AUTOSAR XML (schema 00047)
# (C) 2021 HYUNDAI AUTOEVER Corp.
package /Svc_NvM/ClientServerInterfaces
  5 x client server interface, all with is-service=true, service-kind=NON-VOLATILE-RAM-MANAGER:
    NvMAdmin
      operation SetBlockProtection: possible-error=[NvMAdmin/E_NOT_OK, NvMAdmin/E_OK]
        arg ProtectionEnabled: type=boolean, direction=IN
      error E_NOT_OK: error-code=1
      error E_OK: error-code=0
    NvMMirror
      operation ReadRamBlockFromNvM: possible-error=[NvMMirror/E_NOT_OK, NvMMirror/E_OK]
        arg SrcPtr: type=ConstVoidPtr, direction=IN
      operation WriteRamBlockToNvM: possible-error=[NvMMirror/E_NOT_OK, NvMMirror/E_OK]
        arg DstPtr: type=VoidPtr, direction=IN
      error E_NOT_OK: error-code=1
      error E_OK: error-code=0
    NvMNotifyInitBlock
      operation InitBlock: possible-error=NvMNotifyInitBlock/E_OK
        arg InitBlockRequest: type=NvM_InitBlockRequestType, direction=IN
      error E_OK: error-code=0
    NvMNotifyJobFinished
      operation JobFinished: possible-error=NvMNotifyJobFinished/E_OK
        arg BlockRequest: type=NvM_BlockRequestType, direction=IN
        arg JobResult: type=NvM_RequestResultType, direction=IN
      error E_OK: error-code=0
    NvMService
      12 x operation, all with possible-error=[NvMService/E_NOT_OK, NvMService/E_OK]:
        EraseBlock
        GetDataIndex
          arg DataIndexPtr: type=uint8, direction=OUT
        GetErrorStatus
          arg RequestResultPtr: type=NvM_RequestResultType, direction=OUT
        InvalidateNvBlock
        ReadBlock
          arg DstPtr: type=VoidPtr, direction=IN
        ReadPRAMBlock
        RestoreBlockDefaults
          arg DstPtr: type=VoidPtr, direction=IN
        RestorePRAMBlockDefaults
        SetDataIndex
          arg DataIndex: type=uint8, direction=IN
        SetRamBlockStatus
          arg BlockChanged: type=boolean, direction=IN
        WriteBlock
          arg SrcPtr: type=ConstVoidPtr, direction=IN
        WritePRAMBlock
      error E_NOT_OK: error-code=1
      error E_OK: error-code=0
package /Svc_NvM/ImplementationDataTypes
  6 x impl type:
    ConstVoidPtr: category=DATA_REFERENCE, sw-pointer-target-props={target-category=VALUE, base-type=void, sw-impl-policy=CONST}
    NvM_BlockIdType: implementation-data-type=uint16
    NvM_BlockRequestType: compu {0=NVM_READ_BLOCK, 1=NVM_WRITE_BLOCK, 2=NVM_RESTORE_BLOCK_DEFAULTS, 3=NVM_ERASE_NV_BLOCK, 4=NVM_INVALIDATE_NV_BLOCK, 5=NVM_READ_ALL_BLOCK}, implementation-data-type=uint8
    NvM_InitBlockRequestType: compu {0=NVM_INIT_READ_BLOCK, 1=NVM_INIT_RESTORE_BLOCK_DEFAULTS, 2=NVM_INIT_READ_ALL_BLOCK, 3=NVM_INIT_FIRST_INIT_ALL}, implementation-data-type=uint8
    NvM_RequestResultType: compu {0=NVM_REQ_OK, 1=NVM_REQ_NOT_OK, 2=NVM_REQ_PENDING, 3=NVM_REQ_INTEGRITY_FAILED, 4=NVM_REQ_BLOCK_SKIPPED, 5=NVM_REQ_NV_INVALIDATED, 6=NVM_REQ_CANCELED, 7=NVM_REQ_REDUNDANCY_FAILED, 8=NVM_REQ_RESTORED_FROM_ROM, 9=NVM_MAXVALUE}, implementation-data-type=uint8
    VoidPtr: category=DATA_REFERENCE, sw-pointer-target-props={target-category=VALUE, base-type=void}
package /Svc_NvM/ServiceSwComponentTypes
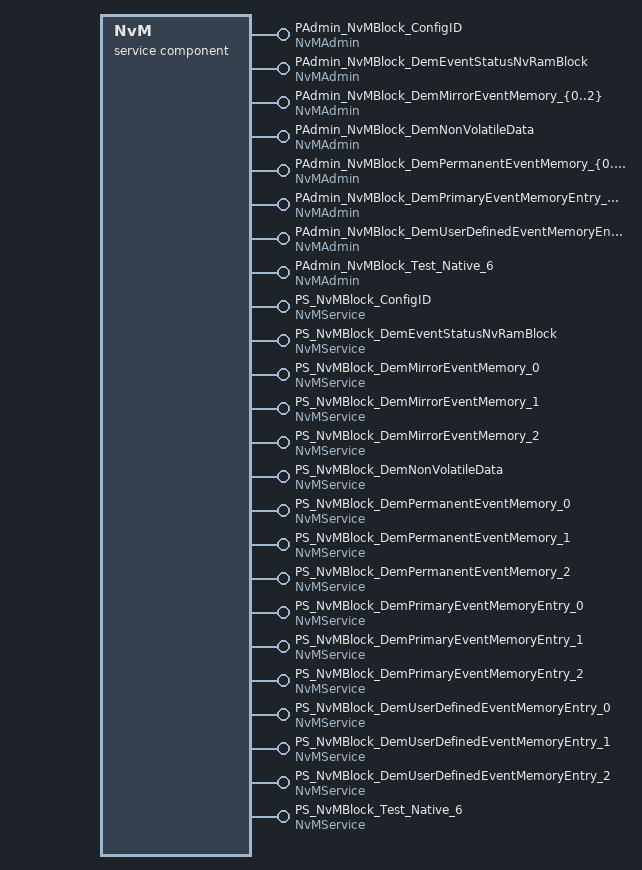
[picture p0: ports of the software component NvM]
  service sw component type NvM
    32 x provide port:
      PAdmin_NvMBlock_ConfigID: server-com-spec{operation=SetBlockProtection, queue-length=1}, provided-interface=NvMAdmin  # This port provides the Supervision status interface of NvMBlock_ConfigID to a SWC.
      PAdmin_NvMBlock_DemEventStatusNvRamBlock: server-com-spec{operation=SetBlockProtection, queue-length=1}, provided-interface=NvMAdmin  # This port provides the Supervision status interface of NvMBlock_DemEventStatusNvRamBlock to a SWC.
      PAdmin_NvMBlock_DemMirrorEventMemory_{0..2}: server-com-spec{operation=SetBlockProtection, queue-length=1}, provided-interface=NvMAdmin  # This port provides the Supervision status interface of NvMBlock_DemMirrorEventMemory_{0..2} to a SWC.
      PAdmin_NvMBlock_DemNonVolatileData: server-com-spec{operation=SetBlockProtection, queue-length=1}, provided-interface=NvMAdmin  # This port provides the Supervision status interface of NvMBlock_DemNonVolatileData to a SWC.
      PAdmin_NvMBlock_DemPermanentEventMemory_{0..2}: server-com-spec{operation=SetBlockProtection, queue-length=1}, provided-interface=NvMAdmin  # This port provides the Supervision status interface of NvMBlock_DemPermanentEventMemory_{0..2} to a SWC.
      PAdmin_NvMBlock_DemPrimaryEventMemoryEntry_{0..2}: server-com-spec{operation=SetBlockProtection, queue-length=1}, provided-interface=NvMAdmin  # This port provides the Supervision status interface of NvMBlock_DemPrimaryEventMemoryEntry_{0..2} to a SWC.
      PAdmin_NvMBlock_DemUserDefinedEventMemoryEntry_{0..2}: server-com-spec{operation=SetBlockProtection, queue-length=1}, provided-interface=NvMAdmin  # This port provides the Supervision status interface of NvMBlock_DemUserDefinedEventMemoryEntry_{0..2} to a SWC.
      PAdmin_NvMBlock_Test_Native_6: server-com-spec{operation=SetBlockProtection, queue-length=1}, provided-interface=NvMAdmin  # This port provides the Supervision status interface of NvMBlock_Test_Native_6 to a SWC.
      PS_NvMBlock_ConfigID: provided-interface=NvMService  # This port provides the Supervision status interface of NvMBlock_ConfigID to a SWC.
        provided-com-specs:
          operation=EraseBlock, queue-length=1
          operation=GetDataIndex, queue-length=1
          operation=GetErrorStatus, queue-length=1
          operation=InvalidateNvBlock, queue-length=1
          operation=ReadBlock, queue-length=1
          operation=ReadPRAMBlock, queue-length=1
          operation=RestoreBlockDefaults, queue-length=1
          operation=RestorePRAMBlockDefaults, queue-length=1
          operation=SetDataIndex, queue-length=1
          operation=SetRamBlockStatus, queue-length=1
          operation=WriteBlock, queue-length=1
          operation=WritePRAMBlock, queue-length=1
      PS_NvMBlock_DemEventStatusNvRamBlock: provided-interface=NvMService  # This port provides the Supervision status interface of NvMBlock_DemEventStatusNvRamBlock to a SWC.
        provided-com-specs:
          operation=EraseBlock, queue-length=1
          operation=GetDataIndex, queue-length=1
          operation=GetErrorStatus, queue-length=1
          operation=InvalidateNvBlock, queue-length=1
          operation=ReadBlock, queue-length=1
          operation=ReadPRAMBlock, queue-length=1
          operation=RestoreBlockDefaults, queue-length=1
          operation=RestorePRAMBlockDefaults, queue-length=1
          operation=SetDataIndex, queue-length=1
          operation=SetRamBlockStatus, queue-length=1
          operation=WriteBlock, queue-length=1
          operation=WritePRAMBlock, queue-length=1
      PS_NvMBlock_DemMirrorEventMemory_0: provided-interface=NvMService  # This port provides the Supervision status interface of NvMBlock_DemMirrorEventMemory_0 to a SWC.
        provided-com-specs:
          operation=EraseBlock, queue-length=1
          operation=GetDataIndex, queue-length=1
          operation=GetErrorStatus, queue-length=1
          operation=InvalidateNvBlock, queue-length=1
          operation=ReadBlock, queue-length=1
          operation=ReadPRAMBlock, queue-length=1
          operation=RestoreBlockDefaults, queue-length=1
          operation=RestorePRAMBlockDefaults, queue-length=1
          operation=SetDataIndex, queue-length=1
          operation=SetRamBlockStatus, queue-length=1
          operation=WriteBlock, queue-length=1
          operation=WritePRAMBlock, queue-length=1
      PS_NvMBlock_DemMirrorEventMemory_1: provided-interface=NvMService  # This port provides the Supervision status interface of NvMBlock_DemMirrorEventMemory_1 to a SWC.
        provided-com-specs:
          operation=EraseBlock, queue-length=1
          operation=GetDataIndex, queue-length=1
          operation=GetErrorStatus, queue-length=1
          operation=InvalidateNvBlock, queue-length=1
          operation=ReadBlock, queue-length=1
          operation=ReadPRAMBlock, queue-length=1
          operation=RestoreBlockDefaults, queue-length=1
          operation=RestorePRAMBlockDefaults, queue-length=1
          operation=SetDataIndex, queue-length=1
          operation=SetRamBlockStatus, queue-length=1
          operation=WriteBlock, queue-length=1
          operation=WritePRAMBlock, queue-length=1
      PS_NvMBlock_DemMirrorEventMemory_2: provided-interface=NvMService  # This port provides the Supervision status interface of NvMBlock_DemMirrorEventMemory_2 to a SWC.
        provided-com-specs:
          operation=EraseBlock, queue-length=1
          operation=GetDataIndex, queue-length=1
          operation=GetErrorStatus, queue-length=1
          operation=InvalidateNvBlock, queue-length=1
          operation=ReadBlock, queue-length=1
          operation=ReadPRAMBlock, queue-length=1
          operation=RestoreBlockDefaults, queue-length=1
          operation=RestorePRAMBlockDefaults, queue-length=1
          operation=SetDataIndex, queue-length=1
          operation=SetRamBlockStatus, queue-length=1
          operation=WriteBlock, queue-length=1
          operation=WritePRAMBlock, queue-length=1
      PS_NvMBlock_DemNonVolatileData: provided-interface=NvMService  # This port provides the Supervision status interface of NvMBlock_DemNonVolatileData to a SWC.
        provided-com-specs:
          operation=EraseBlock, queue-length=1
          operation=GetDataIndex, queue-length=1
          operation=GetErrorStatus, queue-length=1
          operation=InvalidateNvBlock, queue-length=1
          operation=ReadBlock, queue-length=1
          operation=ReadPRAMBlock, queue-length=1
          operation=RestoreBlockDefaults, queue-length=1
          operation=RestorePRAMBlockDefaults, queue-length=1
          operation=SetDataIndex, queue-length=1
          operation=SetRamBlockStatus, queue-length=1
          operation=WriteBlock, queue-length=1
          operation=WritePRAMBlock, queue-length=1
      PS_NvMBlock_DemPermanentEventMemory_0: provided-interface=NvMService  # This port provides the Supervision status interface of NvMBlock_DemPermanentEventMemory_0 to a SWC.
        provided-com-specs:
          operation=EraseBlock, queue-length=1
          operation=GetDataIndex, queue-length=1
          operation=GetErrorStatus, queue-length=1
          operation=InvalidateNvBlock, queue-length=1
          operation=ReadBlock, queue-length=1
          operation=ReadPRAMBlock, queue-length=1
          operation=RestoreBlockDefaults, queue-length=1
          operation=RestorePRAMBlockDefaults, queue-length=1
          operation=SetDataIndex, queue-length=1
          operation=SetRamBlockStatus, queue-length=1
          operation=WriteBlock, queue-length=1
          operation=WritePRAMBlock, queue-length=1
      PS_NvMBlock_DemPermanentEventMemory_1: provided-interface=NvMService  # This port provides the Supervision status interface of NvMBlock_DemPermanentEventMemory_1 to a SWC.
        provided-com-specs:
          operation=EraseBlock, queue-length=1
          operation=GetDataIndex, queue-length=1
          operation=GetErrorStatus, queue-length=1
          operation=InvalidateNvBlock, queue-length=1
          operation=ReadBlock, queue-length=1
          operation=ReadPRAMBlock, queue-length=1
          operation=RestoreBlockDefaults, queue-length=1
          operation=RestorePRAMBlockDefaults, queue-length=1
          operation=SetDataIndex, queue-length=1
          operation=SetRamBlockStatus, queue-length=1
          operation=WriteBlock, queue-length=1
          operation=WritePRAMBlock, queue-length=1
      PS_NvMBlock_DemPermanentEventMemory_2: provided-interface=NvMService  # This port provides the Supervision status interface of NvMBlock_DemPermanentEventMemory_2 to a SWC.
        provided-com-specs:
          operation=EraseBlock, queue-length=1
          operation=GetDataIndex, queue-length=1
          operation=GetErrorStatus, queue-length=1
          operation=InvalidateNvBlock, queue-length=1
          operation=ReadBlock, queue-length=1
          operation=ReadPRAMBlock, queue-length=1
          operation=RestoreBlockDefaults, queue-length=1
          operation=RestorePRAMBlockDefaults, queue-length=1
          operation=SetDataIndex, queue-length=1
          operation=SetRamBlockStatus, queue-length=1
          operation=WriteBlock, queue-length=1
          operation=WritePRAMBlock, queue-length=1
      PS_NvMBlock_DemPrimaryEventMemoryEntry_0: provided-interface=NvMService  # This port provides the Supervision status interface of NvMBlock_DemPrimaryEventMemoryEntry_0 to a SWC.
        provided-com-specs:
          operation=EraseBlock, queue-length=1
          operation=GetDataIndex, queue-length=1
          operation=GetErrorStatus, queue-length=1
          operation=InvalidateNvBlock, queue-length=1
          operation=ReadBlock, queue-length=1
          operation=ReadPRAMBlock, queue-length=1
          operation=RestoreBlockDefaults, queue-length=1
          operation=RestorePRAMBlockDefaults, queue-length=1
          operation=SetDataIndex, queue-length=1
          operation=SetRamBlockStatus, queue-length=1
          operation=WriteBlock, queue-length=1
          operation=WritePRAMBlock, queue-length=1
      PS_NvMBlock_DemPrimaryEventMemoryEntry_1: provided-interface=NvMService  # This port provides the Supervision status interface of NvMBlock_DemPrimaryEventMemoryEntry_1 to a SWC.
        provided-com-specs:
          operation=EraseBlock, queue-length=1
          operation=GetDataIndex, queue-length=1
          operation=GetErrorStatus, queue-length=1
          operation=InvalidateNvBlock, queue-length=1
          operation=ReadBlock, queue-length=1
          operation=ReadPRAMBlock, queue-length=1
          operation=RestoreBlockDefaults, queue-length=1
          operation=RestorePRAMBlockDefaults, queue-length=1
          operation=SetDataIndex, queue-length=1
          operation=SetRamBlockStatus, queue-length=1
          operation=WriteBlock, queue-length=1
          operation=WritePRAMBlock, queue-length=1
      PS_NvMBlock_DemPrimaryEventMemoryEntry_2: provided-interface=NvMService  # This port provides the Supervision status interface of NvMBlock_DemPrimaryEventMemoryEntry_2 to a SWC.
        provided-com-specs:
          operation=EraseBlock, queue-length=1
          operation=GetDataIndex, queue-length=1
          operation=GetErrorStatus, queue-length=1
          operation=InvalidateNvBlock, queue-length=1
          operation=ReadBlock, queue-length=1
          operation=ReadPRAMBlock, queue-length=1
          operation=RestoreBlockDefaults, queue-length=1
          operation=RestorePRAMBlockDefaults, queue-length=1
          operation=SetDataIndex, queue-length=1
          operation=SetRamBlockStatus, queue-length=1
          operation=WriteBlock, queue-length=1
          operation=WritePRAMBlock, queue-length=1
      PS_NvMBlock_DemUserDefinedEventMemoryEntry_0: provided-interface=NvMService  # This port provides the Supervision status interface of NvMBlock_DemUserDefinedEventMemoryEntry_0 to a SWC.
        provided-com-specs:
          operation=EraseBlock, queue-length=1
          operation=GetDataIndex, queue-length=1
          operation=GetErrorStatus, queue-length=1
          operation=InvalidateNvBlock, queue-length=1
          operation=ReadBlock, queue-length=1
          operation=ReadPRAMBlock, queue-length=1
          operation=RestoreBlockDefaults, queue-length=1
          operation=RestorePRAMBlockDefaults, queue-length=1
          operation=SetDataIndex, queue-length=1
          operation=SetRamBlockStatus, queue-length=1
          operation=WriteBlock, queue-length=1
          operation=WritePRAMBlock, queue-length=1
      PS_NvMBlock_DemUserDefinedEventMemoryEntry_1: provided-interface=NvMService  # This port provides the Supervision status interface of NvMBlock_DemUserDefinedEventMemoryEntry_1 to a SWC.
        provided-com-specs:
          operation=EraseBlock, queue-length=1
          operation=GetDataIndex, queue-length=1
          operation=GetErrorStatus, queue-length=1
          operation=InvalidateNvBlock, queue-length=1
          operation=ReadBlock, queue-length=1
          operation=ReadPRAMBlock, queue-length=1
          operation=RestoreBlockDefaults, queue-length=1
          operation=RestorePRAMBlockDefaults, queue-length=1
          operation=SetDataIndex, queue-length=1
          operation=SetRamBlockStatus, queue-length=1
          operation=WriteBlock, queue-length=1
          operation=WritePRAMBlock, queue-length=1
      PS_NvMBlock_DemUserDefinedEventMemoryEntry_2: provided-interface=NvMService  # This port provides the Supervision status interface of NvMBlock_DemUserDefinedEventMemoryEntry_2 to a SWC.
        provided-com-specs:
          operation=EraseBlock, queue-length=1
          operation=GetDataIndex, queue-length=1
          operation=GetErrorStatus, queue-length=1
          operation=InvalidateNvBlock, queue-length=1
          operation=ReadBlock, queue-length=1
          operation=ReadPRAMBlock, queue-length=1
          operation=RestoreBlockDefaults, queue-length=1
          operation=RestorePRAMBlockDefaults, queue-length=1
          operation=SetDataIndex, queue-length=1
          operation=SetRamBlockStatus, queue-length=1
          operation=WriteBlock, queue-length=1
          operation=WritePRAMBlock, queue-length=1
      PS_NvMBlock_Test_Native_6: provided-interface=NvMService  # This port provides the Supervision status interface of NvMBlock_Test_Native_6 to a SWC.
        provided-com-specs:
          operation=EraseBlock, queue-length=1
          operation=GetDataIndex, queue-length=1
          operation=GetErrorStatus, queue-length=1
          operation=InvalidateNvBlock, queue-length=1
          operation=ReadBlock, queue-length=1
          operation=ReadPRAMBlock, queue-length=1
          operation=RestoreBlockDefaults, queue-length=1
          operation=RestorePRAMBlockDefaults, queue-length=1
          operation=SetDataIndex, queue-length=1
          operation=SetRamBlockStatus, queue-length=1
          operation=WriteBlock, queue-length=1
          operation=WritePRAMBlock, queue-length=1
    behavior IB_NvM: handle-termination-and-restart=NO-SUPPORT
      208 x operation invoked event:
        OperationInvokedEvent_PAdmin_NvMBlock_ConfigID_SetBlockProtection: start-on-event=SetBlockProtection, operation=PAdmin_NvMBlock_ConfigID.SetBlockProtection
        OperationInvokedEvent_PAdmin_NvMBlock_DemEventStatusNvRamBlock_SetBlockProtection: start-on-event=SetBlockProtection, operation=PAdmin_NvMBlock_DemEventStatusNvRamBlock.SetBlockProtection
        OperationInvokedEvent_PAdmin_NvMBlock_DemMirrorEventMemory_{0..2}_SetBlockProtection: start-on-event=SetBlockProtection, operation=PAdmin_NvMBlock_DemMirrorEventMemory_{0..2}.SetBlockProtection
        OperationInvokedEvent_PAdmin_NvMBlock_DemNonVolatileData_SetBlockProtection: start-on-event=SetBlockProtection, operation=PAdmin_NvMBlock_DemNonVolatileData.SetBlockProtection
        OperationInvokedEvent_PAdmin_NvMBlock_DemPermanentEventMemory_{0..2}_SetBlockProtection: start-on-event=SetBlockProtection, operation=PAdmin_NvMBlock_DemPermanentEventMemory_{0..2}.SetBlockProtection
        OperationInvokedEvent_PAdmin_NvMBlock_DemPrimaryEventMemoryEntry_{0..2}_SetBlockProtection: start-on-event=SetBlockProtection, operation=PAdmin_NvMBlock_DemPrimaryEventMemoryEntry_{0..2}.SetBlockProtection
        OperationInvokedEvent_PAdmin_NvMBlock_DemUserDefinedEventMemoryEntry_{0..2}_SetBlockProtection: start-on-event=SetBlockProtection, operation=PAdmin_NvMBlock_DemUserDefinedEventMemoryEntry_{0..2}.SetBlockProtection
        OperationInvokedEvent_PAdmin_NvMBlock_Test_Native_6_SetBlockProtection: start-on-event=SetBlockProtection, operation=PAdmin_NvMBlock_Test_Native_6.SetBlockProtection
        OperationInvokedEvent_PS_NvMBlock_ConfigID_EraseBlock: start-on-event=EraseBlock, operation=PS_NvMBlock_ConfigID.EraseBlock
        OperationInvokedEvent_PS_NvMBlock_ConfigID_GetDataIndex: start-on-event=GetDataIndex, operation=PS_NvMBlock_ConfigID.GetDataIndex
        OperationInvokedEvent_PS_NvMBlock_ConfigID_GetErrorStatus: start-on-event=GetErrorStatus, operation=PS_NvMBlock_ConfigID.GetErrorStatus
        OperationInvokedEvent_PS_NvMBlock_ConfigID_InvalidateNvBlock: start-on-event=InvalidateNvBlock, operation=PS_NvMBlock_ConfigID.InvalidateNvBlock
        OperationInvokedEvent_PS_NvMBlock_ConfigID_ReadBlock: start-on-event=ReadBlock, operation=PS_NvMBlock_ConfigID.ReadBlock
        OperationInvokedEvent_PS_NvMBlock_ConfigID_ReadPRAMBlock: start-on-event=ReadPRAMBlock, operation=PS_NvMBlock_ConfigID.ReadPRAMBlock
        OperationInvokedEvent_PS_NvMBlock_ConfigID_RestoreBlockDefaults: start-on-event=RestoreBlockDefaults, operation=PS_NvMBlock_ConfigID.RestoreBlockDefaults
        OperationInvokedEvent_PS_NvMBlock_ConfigID_RestorePRAMBlockDefaults: start-on-event=RestorePRAMBlockDefaults, operation=PS_NvMBlock_ConfigID.RestorePRAMBlockDefaults
        OperationInvokedEvent_PS_NvMBlock_ConfigID_SetDataIndex: start-on-event=SetDataIndex, operation=PS_NvMBlock_ConfigID.SetDataIndex
        OperationInvokedEvent_PS_NvMBlock_ConfigID_SetRamBlockStatus: start-on-event=SetRamBlockStatus, operation=PS_NvMBlock_ConfigID.SetRamBlockStatus
        OperationInvokedEvent_PS_NvMBlock_ConfigID_WriteBlock: start-on-event=WriteBlock, operation=PS_NvMBlock_ConfigID.WriteBlock
        OperationInvokedEvent_PS_NvMBlock_ConfigID_WritePRAMBlock: start-on-event=WritePRAMBlock, operation=PS_NvMBlock_ConfigID.WritePRAMBlock
        OperationInvokedEvent_PS_NvMBlock_DemEventStatusNvRamBlock_EraseBlock: start-on-event=EraseBlock, operation=PS_NvMBlock_DemEventStatusNvRamBlock.EraseBlock
        OperationInvokedEvent_PS_NvMBlock_DemEventStatusNvRamBlock_GetDataIndex: start-on-event=GetDataIndex, operation=PS_NvMBlock_DemEventStatusNvRamBlock.GetDataIndex
        OperationInvokedEvent_PS_NvMBlock_DemEventStatusNvRamBlock_GetErrorStatus: start-on-event=GetErrorStatus, operation=PS_NvMBlock_DemEventStatusNvRamBlock.GetErrorStatus
        OperationInvokedEvent_PS_NvMBlock_DemEventStatusNvRamBlock_InvalidateNvBlock: start-on-event=InvalidateNvBlock, operation=PS_NvMBlock_DemEventStatusNvRamBlock.InvalidateNvBlock
        OperationInvokedEvent_PS_NvMBlock_DemEventStatusNvRamBlock_ReadBlock: start-on-event=ReadBlock, operation=PS_NvMBlock_DemEventStatusNvRamBlock.ReadBlock
        OperationInvokedEvent_PS_NvMBlock_DemEventStatusNvRamBlock_ReadPRAMBlock: start-on-event=ReadPRAMBlock, operation=PS_NvMBlock_DemEventStatusNvRamBlock.ReadPRAMBlock
        OperationInvokedEvent_PS_NvMBlock_DemEventStatusNvRamBlock_RestoreBlockDefaults: start-on-event=RestoreBlockDefaults, operation=PS_NvMBlock_DemEventStatusNvRamBlock.RestoreBlockDefaults
        OperationInvokedEvent_PS_NvMBlock_DemEventStatusNvRamBlock_RestorePRAMBlockDefaults: start-on-event=RestorePRAMBlockDefaults, operation=PS_NvMBlock_DemEventStatusNvRamBlock.RestorePRAMBlockDefaults
        OperationInvokedEvent_PS_NvMBlock_DemEventStatusNvRamBlock_SetDataIndex: start-on-event=SetDataIndex, operation=PS_NvMBlock_DemEventStatusNvRamBlock.SetDataIndex
        OperationInvokedEvent_PS_NvMBlock_DemEventStatusNvRamBlock_SetRamBlockStatus: start-on-event=SetRamBlockStatus, operation=PS_NvMBlock_DemEventStatusNvRamBlock.SetRamBlockStatus
        OperationInvokedEvent_PS_NvMBlock_DemEventStatusNvRamBlock_WriteBlock: start-on-event=WriteBlock, operation=PS_NvMBlock_DemEventStatusNvRamBlock.WriteBlock
        OperationInvokedEvent_PS_NvMBlock_DemEventStatusNvRamBlock_WritePRAMBlock: start-on-event=WritePRAMBlock, operation=PS_NvMBlock_DemEventStatusNvRamBlock.WritePRAMBlock
        OperationInvokedEvent_PS_NvMBlock_DemMirrorEventMemory_0_EraseBlock: start-on-event=EraseBlock, operation=PS_NvMBlock_DemMirrorEventMemory_0.EraseBlock
        OperationInvokedEvent_PS_NvMBlock_DemMirrorEventMemory_0_GetDataIndex: start-on-event=GetDataIndex, operation=PS_NvMBlock_DemMirrorEventMemory_0.GetDataIndex
        OperationInvokedEvent_PS_NvMBlock_DemMirrorEventMemory_0_GetErrorStatus: start-on-event=GetErrorStatus, operation=PS_NvMBlock_DemMirrorEventMemory_0.GetErrorStatus
        OperationInvokedEvent_PS_NvMBlock_DemMirrorEventMemory_0_InvalidateNvBlock: start-on-event=InvalidateNvBlock, operation=PS_NvMBlock_DemMirrorEventMemory_0.InvalidateNvBlock
        OperationInvokedEvent_PS_NvMBlock_DemMirrorEventMemory_0_ReadBlock: start-on-event=ReadBlock, operation=PS_NvMBlock_DemMirrorEventMemory_0.ReadBlock
        OperationInvokedEvent_PS_NvMBlock_DemMirrorEventMemory_0_ReadPRAMBlock: start-on-event=ReadPRAMBlock, operation=PS_NvMBlock_DemMirrorEventMemory_0.ReadPRAMBlock
        OperationInvokedEvent_PS_NvMBlock_DemMirrorEventMemory_0_RestoreBlockDefaults: start-on-event=RestoreBlockDefaults, operation=PS_NvMBlock_DemMirrorEventMemory_0.RestoreBlockDefaults
        OperationInvokedEvent_PS_NvMBlock_DemMirrorEventMemory_0_RestorePRAMBlockDefaults: start-on-event=RestorePRAMBlockDefaults, operation=PS_NvMBlock_DemMirrorEventMemory_0.RestorePRAMBlockDefaults
        OperationInvokedEvent_PS_NvMBlock_DemMirrorEventMemory_0_SetDataIndex: start-on-event=SetDataIndex, operation=PS_NvMBlock_DemMirrorEventMemory_0.SetDataIndex
        OperationInvokedEvent_PS_NvMBlock_DemMirrorEventMemory_0_SetRamBlockStatus: start-on-event=SetRamBlockStatus, operation=PS_NvMBlock_DemMirrorEventMemory_0.SetRamBlockStatus
        OperationInvokedEvent_PS_NvMBlock_DemMirrorEventMemory_0_WriteBlock: start-on-event=WriteBlock, operation=PS_NvMBlock_DemMirrorEventMemory_0.WriteBlock
        OperationInvokedEvent_PS_NvMBlock_DemMirrorEventMemory_0_WritePRAMBlock: start-on-event=WritePRAMBlock, operation=PS_NvMBlock_DemMirrorEventMemory_0.WritePRAMBlock
        OperationInvokedEvent_PS_NvMBlock_DemMirrorEventMemory_1_EraseBlock: start-on-event=EraseBlock, operation=PS_NvMBlock_DemMirrorEventMemory_1.EraseBlock
        OperationInvokedEvent_PS_NvMBlock_DemMirrorEventMemory_1_GetDataIndex: start-on-event=GetDataIndex, operation=PS_NvMBlock_DemMirrorEventMemory_1.GetDataIndex
        OperationInvokedEvent_PS_NvMBlock_DemMirrorEventMemory_1_GetErrorStatus: start-on-event=GetErrorStatus, operation=PS_NvMBlock_DemMirrorEventMemory_1.GetErrorStatus
        OperationInvokedEvent_PS_NvMBlock_DemMirrorEventMemory_1_InvalidateNvBlock: start-on-event=InvalidateNvBlock, operation=PS_NvMBlock_DemMirrorEventMemory_1.InvalidateNvBlock
        OperationInvokedEvent_PS_NvMBlock_DemMirrorEventMemory_1_ReadBlock: start-on-event=ReadBlock, operation=PS_NvMBlock_DemMirrorEventMemory_1.ReadBlock
        OperationInvokedEvent_PS_NvMBlock_DemMirrorEventMemory_1_ReadPRAMBlock: start-on-event=ReadPRAMBlock, operation=PS_NvMBlock_DemMirrorEventMemory_1.ReadPRAMBlock
        OperationInvokedEvent_PS_NvMBlock_DemMirrorEventMemory_1_RestoreBlockDefaults: start-on-event=RestoreBlockDefaults, operation=PS_NvMBlock_DemMirrorEventMemory_1.RestoreBlockDefaults
        OperationInvokedEvent_PS_NvMBlock_DemMirrorEventMemory_1_RestorePRAMBlockDefaults: start-on-event=RestorePRAMBlockDefaults, operation=PS_NvMBlock_DemMirrorEventMemory_1.RestorePRAMBlockDefaults
        OperationInvokedEvent_PS_NvMBlock_DemMirrorEventMemory_1_SetDataIndex: start-on-event=SetDataIndex, operation=PS_NvMBlock_DemMirrorEventMemory_1.SetDataIndex
        OperationInvokedEvent_PS_NvMBlock_DemMirrorEventMemory_1_SetRamBlockStatus: start-on-event=SetRamBlockStatus, operation=PS_NvMBlock_DemMirrorEventMemory_1.SetRamBlockStatus
        OperationInvokedEvent_PS_NvMBlock_DemMirrorEventMemory_1_WriteBlock: start-on-event=WriteBlock, operation=PS_NvMBlock_DemMirrorEventMemory_1.WriteBlock
        OperationInvokedEvent_PS_NvMBlock_DemMirrorEventMemory_1_WritePRAMBlock: start-on-event=WritePRAMBlock, operation=PS_NvMBlock_DemMirrorEventMemory_1.WritePRAMBlock
        OperationInvokedEvent_PS_NvMBlock_DemMirrorEventMemory_2_EraseBlock: start-on-event=EraseBlock, operation=PS_NvMBlock_DemMirrorEventMemory_2.EraseBlock
        OperationInvokedEvent_PS_NvMBlock_DemMirrorEventMemory_2_GetDataIndex: start-on-event=GetDataIndex, operation=PS_NvMBlock_DemMirrorEventMemory_2.GetDataIndex
        OperationInvokedEvent_PS_NvMBlock_DemMirrorEventMemory_2_GetErrorStatus: start-on-event=GetErrorStatus, operation=PS_NvMBlock_DemMirrorEventMemory_2.GetErrorStatus
        OperationInvokedEvent_PS_NvMBlock_DemMirrorEventMemory_2_InvalidateNvBlock: start-on-event=InvalidateNvBlock, operation=PS_NvMBlock_DemMirrorEventMemory_2.InvalidateNvBlock
        OperationInvokedEvent_PS_NvMBlock_DemMirrorEventMemory_2_ReadBlock: start-on-event=ReadBlock, operation=PS_NvMBlock_DemMirrorEventMemory_2.ReadBlock
        OperationInvokedEvent_PS_NvMBlock_DemMirrorEventMemory_2_ReadPRAMBlock: start-on-event=ReadPRAMBlock, operation=PS_NvMBlock_DemMirrorEventMemory_2.ReadPRAMBlock
        OperationInvokedEvent_PS_NvMBlock_DemMirrorEventMemory_2_RestoreBlockDefaults: start-on-event=RestoreBlockDefaults, operation=PS_NvMBlock_DemMirrorEventMemory_2.RestoreBlockDefaults
        OperationInvokedEvent_PS_NvMBlock_DemMirrorEventMemory_2_RestorePRAMBlockDefaults: start-on-event=RestorePRAMBlockDefaults, operation=PS_NvMBlock_DemMirrorEventMemory_2.RestorePRAMBlockDefaults
        OperationInvokedEvent_PS_NvMBlock_DemMirrorEventMemory_2_SetDataIndex: start-on-event=SetDataIndex, operation=PS_NvMBlock_DemMirrorEventMemory_2.SetDataIndex
        OperationInvokedEvent_PS_NvMBlock_DemMirrorEventMemory_2_SetRamBlockStatus: start-on-event=SetRamBlockStatus, operation=PS_NvMBlock_DemMirrorEventMemory_2.SetRamBlockStatus
        OperationInvokedEvent_PS_NvMBlock_DemMirrorEventMemory_2_WriteBlock: start-on-event=WriteBlock, operation=PS_NvMBlock_DemMirrorEventMemory_2.WriteBlock
        OperationInvokedEvent_PS_NvMBlock_DemMirrorEventMemory_2_WritePRAMBlock: start-on-event=WritePRAMBlock, operation=PS_NvMBlock_DemMirrorEventMemory_2.WritePRAMBlock
        OperationInvokedEvent_PS_NvMBlock_DemNonVolatileData_EraseBlock: start-on-event=EraseBlock, operation=PS_NvMBlock_DemNonVolatileData.EraseBlock
        OperationInvokedEvent_PS_NvMBlock_DemNonVolatileData_GetDataIndex: start-on-event=GetDataIndex, operation=PS_NvMBlock_DemNonVolatileData.GetDataIndex
        OperationInvokedEvent_PS_NvMBlock_DemNonVolatileData_GetErrorStatus: start-on-event=GetErrorStatus, operation=PS_NvMBlock_DemNonVolatileData.GetErrorStatus
        OperationInvokedEvent_PS_NvMBlock_DemNonVolatileData_InvalidateNvBlock: start-on-event=InvalidateNvBlock, operation=PS_NvMBlock_DemNonVolatileData.InvalidateNvBlock
        OperationInvokedEvent_PS_NvMBlock_DemNonVolatileData_ReadBlock: start-on-event=ReadBlock, operation=PS_NvMBlock_DemNonVolatileData.ReadBlock
        OperationInvokedEvent_PS_NvMBlock_DemNonVolatileData_ReadPRAMBlock: start-on-event=ReadPRAMBlock, operation=PS_NvMBlock_DemNonVolatileData.ReadPRAMBlock
        OperationInvokedEvent_PS_NvMBlock_DemNonVolatileData_RestoreBlockDefaults: start-on-event=RestoreBlockDefaults, operation=PS_NvMBlock_DemNonVolatileData.RestoreBlockDefaults
        OperationInvokedEvent_PS_NvMBlock_DemNonVolatileData_RestorePRAMBlockDefaults: start-on-event=RestorePRAMBlockDefaults, operation=PS_NvMBlock_DemNonVolatileData.RestorePRAMBlockDefaults
        OperationInvokedEvent_PS_NvMBlock_DemNonVolatileData_SetDataIndex: start-on-event=SetDataIndex, operation=PS_NvMBlock_DemNonVolatileData.SetDataIndex
        OperationInvokedEvent_PS_NvMBlock_DemNonVolatileData_SetRamBlockStatus: start-on-event=SetRamBlockStatus, operation=PS_NvMBlock_DemNonVolatileData.SetRamBlockStatus
        OperationInvokedEvent_PS_NvMBlock_DemNonVolatileData_WriteBlock: start-on-event=WriteBlock, operation=PS_NvMBlock_DemNonVolatileData.WriteBlock
        OperationInvokedEvent_PS_NvMBlock_DemNonVolatileData_WritePRAMBlock: start-on-event=WritePRAMBlock, operation=PS_NvMBlock_DemNonVolatileData.WritePRAMBlock
        OperationInvokedEvent_PS_NvMBlock_DemPermanentEventMemory_0_EraseBlock: start-on-event=EraseBlock, operation=PS_NvMBlock_DemPermanentEventMemory_0.EraseBlock
        OperationInvokedEvent_PS_NvMBlock_DemPermanentEventMemory_0_GetDataIndex: start-on-event=GetDataIndex, operation=PS_NvMBlock_DemPermanentEventMemory_0.GetDataIndex
        OperationInvokedEvent_PS_NvMBlock_DemPermanentEventMemory_0_GetErrorStatus: start-on-event=GetErrorStatus, operation=PS_NvMBlock_DemPermanentEventMemory_0.GetErrorStatus
        OperationInvokedEvent_PS_NvMBlock_DemPermanentEventMemory_0_InvalidateNvBlock: start-on-event=InvalidateNvBlock, operation=PS_NvMBlock_DemPermanentEventMemory_0.InvalidateNvBlock
        OperationInvokedEvent_PS_NvMBlock_DemPermanentEventMemory_0_ReadBlock: start-on-event=ReadBlock, operation=PS_NvMBlock_DemPermanentEventMemory_0.ReadBlock
        OperationInvokedEvent_PS_NvMBlock_DemPermanentEventMemory_0_ReadPRAMBlock: start-on-event=ReadPRAMBlock, operation=PS_NvMBlock_DemPermanentEventMemory_0.ReadPRAMBlock
        OperationInvokedEvent_PS_NvMBlock_DemPermanentEventMemory_0_RestoreBlockDefaults: start-on-event=RestoreBlockDefaults, operation=PS_NvMBlock_DemPermanentEventMemory_0.RestoreBlockDefaults
        OperationInvokedEvent_PS_NvMBlock_DemPermanentEventMemory_0_RestorePRAMBlockDefaults: start-on-event=RestorePRAMBlockDefaults, operation=PS_NvMBlock_DemPermanentEventMemory_0.RestorePRAMBlockDefaults
        OperationInvokedEvent_PS_NvMBlock_DemPermanentEventMemory_0_SetDataIndex: start-on-event=SetDataIndex, operation=PS_NvMBlock_DemPermanentEventMemory_0.SetDataIndex
        OperationInvokedEvent_PS_NvMBlock_DemPermanentEventMemory_0_SetRamBlockStatus: start-on-event=SetRamBlockStatus, operation=PS_NvMBlock_DemPermanentEventMemory_0.SetRamBlockStatus
        OperationInvokedEvent_PS_NvMBlock_DemPermanentEventMemory_0_WriteBlock: start-on-event=WriteBlock, operation=PS_NvMBlock_DemPermanentEventMemory_0.WriteBlock
        OperationInvokedEvent_PS_NvMBlock_DemPermanentEventMemory_0_WritePRAMBlock: start-on-event=WritePRAMBlock, operation=PS_NvMBlock_DemPermanentEventMemory_0.WritePRAMBlock
        OperationInvokedEvent_PS_NvMBlock_DemPermanentEventMemory_1_EraseBlock: start-on-event=EraseBlock, operation=PS_NvMBlock_DemPermanentEventMemory_1.EraseBlock
        OperationInvokedEvent_PS_NvMBlock_DemPermanentEventMemory_1_GetDataIndex: start-on-event=GetDataIndex, operation=PS_NvMBlock_DemPermanentEventMemory_1.GetDataIndex
        OperationInvokedEvent_PS_NvMBlock_DemPermanentEventMemory_1_GetErrorStatus: start-on-event=GetErrorStatus, operation=PS_NvMBlock_DemPermanentEventMemory_1.GetErrorStatus
        OperationInvokedEvent_PS_NvMBlock_DemPermanentEventMemory_1_InvalidateNvBlock: start-on-event=InvalidateNvBlock, operation=PS_NvMBlock_DemPermanentEventMemory_1.InvalidateNvBlock
        OperationInvokedEvent_PS_NvMBlock_DemPermanentEventMemory_1_ReadBlock: start-on-event=ReadBlock, operation=PS_NvMBlock_DemPermanentEventMemory_1.ReadBlock
        OperationInvokedEvent_PS_NvMBlock_DemPermanentEventMemory_1_ReadPRAMBlock: start-on-event=ReadPRAMBlock, operation=PS_NvMBlock_DemPermanentEventMemory_1.ReadPRAMBlock
        OperationInvokedEvent_PS_NvMBlock_DemPermanentEventMemory_1_RestoreBlockDefaults: start-on-event=RestoreBlockDefaults, operation=PS_NvMBlock_DemPermanentEventMemory_1.RestoreBlockDefaults
        OperationInvokedEvent_PS_NvMBlock_DemPermanentEventMemory_1_RestorePRAMBlockDefaults: start-on-event=RestorePRAMBlockDefaults, operation=PS_NvMBlock_DemPermanentEventMemory_1.RestorePRAMBlockDefaults
        OperationInvokedEvent_PS_NvMBlock_DemPermanentEventMemory_1_SetDataIndex: start-on-event=SetDataIndex, operation=PS_NvMBlock_DemPermanentEventMemory_1.SetDataIndex
        OperationInvokedEvent_PS_NvMBlock_DemPermanentEventMemory_1_SetRamBlockStatus: start-on-event=SetRamBlockStatus, operation=PS_NvMBlock_DemPermanentEventMemory_1.SetRamBlockStatus
        OperationInvokedEvent_PS_NvMBlock_DemPermanentEventMemory_1_WriteBlock: start-on-event=WriteBlock, operation=PS_NvMBlock_DemPermanentEventMemory_1.WriteBlock
        OperationInvokedEvent_PS_NvMBlock_DemPermanentEventMemory_1_WritePRAMBlock: start-on-event=WritePRAMBlock, operation=PS_NvMBlock_DemPermanentEventMemory_1.WritePRAMBlock
        OperationInvokedEvent_PS_NvMBlock_DemPermanentEventMemory_2_EraseBlock: start-on-event=EraseBlock, operation=PS_NvMBlock_DemPermanentEventMemory_2.EraseBlock
        OperationInvokedEvent_PS_NvMBlock_DemPermanentEventMemory_2_GetDataIndex: start-on-event=GetDataIndex, operation=PS_NvMBlock_DemPermanentEventMemory_2.GetDataIndex
        OperationInvokedEvent_PS_NvMBlock_DemPermanentEventMemory_2_GetErrorStatus: start-on-event=GetErrorStatus, operation=PS_NvMBlock_DemPermanentEventMemory_2.GetErrorStatus
        OperationInvokedEvent_PS_NvMBlock_DemPermanentEventMemory_2_InvalidateNvBlock: start-on-event=InvalidateNvBlock, operation=PS_NvMBlock_DemPermanentEventMemory_2.InvalidateNvBlock
        OperationInvokedEvent_PS_NvMBlock_DemPermanentEventMemory_2_ReadBlock: start-on-event=ReadBlock, operation=PS_NvMBlock_DemPermanentEventMemory_2.ReadBlock
        OperationInvokedEvent_PS_NvMBlock_DemPermanentEventMemory_2_ReadPRAMBlock: start-on-event=ReadPRAMBlock, operation=PS_NvMBlock_DemPermanentEventMemory_2.ReadPRAMBlock
        OperationInvokedEvent_PS_NvMBlock_DemPermanentEventMemory_2_RestoreBlockDefaults: start-on-event=RestoreBlockDefaults, operation=PS_NvMBlock_DemPermanentEventMemory_2.RestoreBlockDefaults
        OperationInvokedEvent_PS_NvMBlock_DemPermanentEventMemory_2_RestorePRAMBlockDefaults: start-on-event=RestorePRAMBlockDefaults, operation=PS_NvMBlock_DemPermanentEventMemory_2.RestorePRAMBlockDefaults
        OperationInvokedEvent_PS_NvMBlock_DemPermanentEventMemory_2_SetDataIndex: start-on-event=SetDataIndex, operation=PS_NvMBlock_DemPermanentEventMemory_2.SetDataIndex
        OperationInvokedEvent_PS_NvMBlock_DemPermanentEventMemory_2_SetRamBlockStatus: start-on-event=SetRamBlockStatus, operation=PS_NvMBlock_DemPermanentEventMemory_2.SetRamBlockStatus
        OperationInvokedEvent_PS_NvMBlock_DemPermanentEventMemory_2_WriteBlock: start-on-event=WriteBlock, operation=PS_NvMBlock_DemPermanentEventMemory_2.WriteBlock
        OperationInvokedEvent_PS_NvMBlock_DemPermanentEventMemory_2_WritePRAMBlock: start-on-event=WritePRAMBlock, operation=PS_NvMBlock_DemPermanentEventMemory_2.WritePRAMBlock
        OperationInvokedEvent_PS_NvMBlock_DemPrimaryEventMemoryEntry_0_EraseBlock: start-on-event=EraseBlock, operation=PS_NvMBlock_DemPrimaryEventMemoryEntry_0.EraseBlock
        OperationInvokedEvent_PS_NvMBlock_DemPrimaryEventMemoryEntry_0_GetDataIndex: start-on-event=GetDataIndex, operation=PS_NvMBlock_DemPrimaryEventMemoryEntry_0.GetDataIndex
        OperationInvokedEvent_PS_NvMBlock_DemPrimaryEventMemoryEntry_0_GetErrorStatus: start-on-event=GetErrorStatus, operation=PS_NvMBlock_DemPrimaryEventMemoryEntry_0.GetErrorStatus
        OperationInvokedEvent_PS_NvMBlock_DemPrimaryEventMemoryEntry_0_InvalidateNvBlock: start-on-event=InvalidateNvBlock, operation=PS_NvMBlock_DemPrimaryEventMemoryEntry_0.InvalidateNvBlock
        OperationInvokedEvent_PS_NvMBlock_DemPrimaryEventMemoryEntry_0_ReadBlock: start-on-event=ReadBlock, operation=PS_NvMBlock_DemPrimaryEventMemoryEntry_0.ReadBlock
        OperationInvokedEvent_PS_NvMBlock_DemPrimaryEventMemoryEntry_0_ReadPRAMBlock: start-on-event=ReadPRAMBlock, operation=PS_NvMBlock_DemPrimaryEventMemoryEntry_0.ReadPRAMBlock
        OperationInvokedEvent_PS_NvMBlock_DemPrimaryEventMemoryEntry_0_RestoreBlockDefaults: start-on-event=RestoreBlockDefaults, operation=PS_NvMBlock_DemPrimaryEventMemoryEntry_0.RestoreBlockDefaults
        OperationInvokedEvent_PS_NvMBlock_DemPrimaryEventMemoryEntry_0_RestorePRAMBlockDefaults: start-on-event=RestorePRAMBlockDefaults, operation=PS_NvMBlock_DemPrimaryEventMemoryEntry_0.RestorePRAMBlockDefaults
        OperationInvokedEvent_PS_NvMBlock_DemPrimaryEventMemoryEntry_0_SetDataIndex: start-on-event=SetDataIndex, operation=PS_NvMBlock_DemPrimaryEventMemoryEntry_0.SetDataIndex
        OperationInvokedEvent_PS_NvMBlock_DemPrimaryEventMemoryEntry_0_SetRamBlockStatus: start-on-event=SetRamBlockStatus, operation=PS_NvMBlock_DemPrimaryEventMemoryEntry_0.SetRamBlockStatus
        OperationInvokedEvent_PS_NvMBlock_DemPrimaryEventMemoryEntry_0_WriteBlock: start-on-event=WriteBlock, operation=PS_NvMBlock_DemPrimaryEventMemoryEntry_0.WriteBlock
        OperationInvokedEvent_PS_NvMBlock_DemPrimaryEventMemoryEntry_0_WritePRAMBlock: start-on-event=WritePRAMBlock, operation=PS_NvMBlock_DemPrimaryEventMemoryEntry_0.WritePRAMBlock
        OperationInvokedEvent_PS_NvMBlock_DemPrimaryEventMemoryEntry_1_EraseBlock: start-on-event=EraseBlock, operation=PS_NvMBlock_DemPrimaryEventMemoryEntry_1.EraseBlock
        OperationInvokedEvent_PS_NvMBlock_DemPrimaryEventMemoryEntry_1_GetDataIndex: start-on-event=GetDataIndex, operation=PS_NvMBlock_DemPrimaryEventMemoryEntry_1.GetDataIndex
        OperationInvokedEvent_PS_NvMBlock_DemPrimaryEventMemoryEntry_1_GetErrorStatus: start-on-event=GetErrorStatus, operation=PS_NvMBlock_DemPrimaryEventMemoryEntry_1.GetErrorStatus
        OperationInvokedEvent_PS_NvMBlock_DemPrimaryEventMemoryEntry_1_InvalidateNvBlock: start-on-event=InvalidateNvBlock, operation=PS_NvMBlock_DemPrimaryEventMemoryEntry_1.InvalidateNvBlock
        OperationInvokedEvent_PS_NvMBlock_DemPrimaryEventMemoryEntry_1_ReadBlock: start-on-event=ReadBlock, operation=PS_NvMBlock_DemPrimaryEventMemoryEntry_1.ReadBlock
        OperationInvokedEvent_PS_NvMBlock_DemPrimaryEventMemoryEntry_1_ReadPRAMBlock: start-on-event=ReadPRAMBlock, operation=PS_NvMBlock_DemPrimaryEventMemoryEntry_1.ReadPRAMBlock
        OperationInvokedEvent_PS_NvMBlock_DemPrimaryEventMemoryEntry_1_RestoreBlockDefaults: start-on-event=RestoreBlockDefaults, operation=PS_NvMBlock_DemPrimaryEventMemoryEntry_1.RestoreBlockDefaults
        OperationInvokedEvent_PS_NvMBlock_DemPrimaryEventMemoryEntry_1_RestorePRAMBlockDefaults: start-on-event=RestorePRAMBlockDefaults, operation=PS_NvMBlock_DemPrimaryEventMemoryEntry_1.RestorePRAMBlockDefaults
        OperationInvokedEvent_PS_NvMBlock_DemPrimaryEventMemoryEntry_1_SetDataIndex: start-on-event=SetDataIndex, operation=PS_NvMBlock_DemPrimaryEventMemoryEntry_1.SetDataIndex
        OperationInvokedEvent_PS_NvMBlock_DemPrimaryEventMemoryEntry_1_SetRamBlockStatus: start-on-event=SetRamBlockStatus, operation=PS_NvMBlock_DemPrimaryEventMemoryEntry_1.SetRamBlockStatus
        OperationInvokedEvent_PS_NvMBlock_DemPrimaryEventMemoryEntry_1_WriteBlock: start-on-event=WriteBlock, operation=PS_NvMBlock_DemPrimaryEventMemoryEntry_1.WriteBlock
        OperationInvokedEvent_PS_NvMBlock_DemPrimaryEventMemoryEntry_1_WritePRAMBlock: start-on-event=WritePRAMBlock, operation=PS_NvMBlock_DemPrimaryEventMemoryEntry_1.WritePRAMBlock
        OperationInvokedEvent_PS_NvMBlock_DemPrimaryEventMemoryEntry_2_EraseBlock: start-on-event=EraseBlock, operation=PS_NvMBlock_DemPrimaryEventMemoryEntry_2.EraseBlock
        OperationInvokedEvent_PS_NvMBlock_DemPrimaryEventMemoryEntry_2_GetDataIndex: start-on-event=GetDataIndex, operation=PS_NvMBlock_DemPrimaryEventMemoryEntry_2.GetDataIndex
        OperationInvokedEvent_PS_NvMBlock_DemPrimaryEventMemoryEntry_2_GetErrorStatus: start-on-event=GetErrorStatus, operation=PS_NvMBlock_DemPrimaryEventMemoryEntry_2.GetErrorStatus
        OperationInvokedEvent_PS_NvMBlock_DemPrimaryEventMemoryEntry_2_InvalidateNvBlock: start-on-event=InvalidateNvBlock, operation=PS_NvMBlock_DemPrimaryEventMemoryEntry_2.InvalidateNvBlock
        OperationInvokedEvent_PS_NvMBlock_DemPrimaryEventMemoryEntry_2_ReadBlock: start-on-event=ReadBlock, operation=PS_NvMBlock_DemPrimaryEventMemoryEntry_2.ReadBlock
        OperationInvokedEvent_PS_NvMBlock_DemPrimaryEventMemoryEntry_2_ReadPRAMBlock: start-on-event=ReadPRAMBlock, operation=PS_NvMBlock_DemPrimaryEventMemoryEntry_2.ReadPRAMBlock
        OperationInvokedEvent_PS_NvMBlock_DemPrimaryEventMemoryEntry_2_RestoreBlockDefaults: start-on-event=RestoreBlockDefaults, operation=PS_NvMBlock_DemPrimaryEventMemoryEntry_2.RestoreBlockDefaults
        OperationInvokedEvent_PS_NvMBlock_DemPrimaryEventMemoryEntry_2_RestorePRAMBlockDefaults: start-on-event=RestorePRAMBlockDefaults, operation=PS_NvMBlock_DemPrimaryEventMemoryEntry_2.RestorePRAMBlockDefaults
        OperationInvokedEvent_PS_NvMBlock_DemPrimaryEventMemoryEntry_2_SetDataIndex: start-on-event=SetDataIndex, operation=PS_NvMBlock_DemPrimaryEventMemoryEntry_2.SetDataIndex
        OperationInvokedEvent_PS_NvMBlock_DemPrimaryEventMemoryEntry_2_SetRamBlockStatus: start-on-event=SetRamBlockStatus, operation=PS_NvMBlock_DemPrimaryEventMemoryEntry_2.SetRamBlockStatus
        OperationInvokedEvent_PS_NvMBlock_DemPrimaryEventMemoryEntry_2_WriteBlock: start-on-event=WriteBlock, operation=PS_NvMBlock_DemPrimaryEventMemoryEntry_2.WriteBlock
        OperationInvokedEvent_PS_NvMBlock_DemPrimaryEventMemoryEntry_2_WritePRAMBlock: start-on-event=WritePRAMBlock, operation=PS_NvMBlock_DemPrimaryEventMemoryEntry_2.WritePRAMBlock
        OperationInvokedEvent_PS_NvMBlock_DemUserDefinedEventMemoryEntry_0_EraseBlock: start-on-event=EraseBlock, operation=PS_NvMBlock_DemUserDefinedEventMemoryEntry_0.EraseBlock
        OperationInvokedEvent_PS_NvMBlock_DemUserDefinedEventMemoryEntry_0_GetDataIndex: start-on-event=GetDataIndex, operation=PS_NvMBlock_DemUserDefinedEventMemoryEntry_0.GetDataIndex
        OperationInvokedEvent_PS_NvMBlock_DemUserDefinedEventMemoryEntry_0_GetErrorStatus: start-on-event=GetErrorStatus, operation=PS_NvMBlock_DemUserDefinedEventMemoryEntry_0.GetErrorStatus
        OperationInvokedEvent_PS_NvMBlock_DemUserDefinedEventMemoryEntry_0_InvalidateNvBlock: start-on-event=InvalidateNvBlock, operation=PS_NvMBlock_DemUserDefinedEventMemoryEntry_0.InvalidateNvBlock
        OperationInvokedEvent_PS_NvMBlock_DemUserDefinedEventMemoryEntry_0_ReadBlock: start-on-event=ReadBlock, operation=PS_NvMBlock_DemUserDefinedEventMemoryEntry_0.ReadBlock
        OperationInvokedEvent_PS_NvMBlock_DemUserDefinedEventMemoryEntry_0_ReadPRAMBlock: start-on-event=ReadPRAMBlock, operation=PS_NvMBlock_DemUserDefinedEventMemoryEntry_0.ReadPRAMBlock
        OperationInvokedEvent_PS_NvMBlock_DemUserDefinedEventMemoryEntry_0_RestoreBlockDefaults: start-on-event=RestoreBlockDefaults, operation=PS_NvMBlock_DemUserDefinedEventMemoryEntry_0.RestoreBlockDefaults
        OperationInvokedEvent_PS_NvMBlock_DemUserDefinedEventMemoryEntry_0_RestorePRAMBlockDefaults: start-on-event=RestorePRAMBlockDefaults, operation=PS_NvMBlock_DemUserDefinedEventMemoryEntry_0.RestorePRAMBlockDefaults
        OperationInvokedEvent_PS_NvMBlock_DemUserDefinedEventMemoryEntry_0_SetDataIndex: start-on-event=SetDataIndex, operation=PS_NvMBlock_DemUserDefinedEventMemoryEntry_0.SetDataIndex
        OperationInvokedEvent_PS_NvMBlock_DemUserDefinedEventMemoryEntry_0_SetRamBlockStatus: start-on-event=SetRamBlockStatus, operation=PS_NvMBlock_DemUserDefinedEventMemoryEntry_0.SetRamBlockStatus
        OperationInvokedEvent_PS_NvMBlock_DemUserDefinedEventMemoryEntry_0_WriteBlock: start-on-event=WriteBlock, operation=PS_NvMBlock_DemUserDefinedEventMemoryEntry_0.WriteBlock
        OperationInvokedEvent_PS_NvMBlock_DemUserDefinedEventMemoryEntry_0_WritePRAMBlock: start-on-event=WritePRAMBlock, operation=PS_NvMBlock_DemUserDefinedEventMemoryEntry_0.WritePRAMBlock
        OperationInvokedEvent_PS_NvMBlock_DemUserDefinedEventMemoryEntry_1_EraseBlock: start-on-event=EraseBlock, operation=PS_NvMBlock_DemUserDefinedEventMemoryEntry_1.EraseBlock
        OperationInvokedEvent_PS_NvMBlock_DemUserDefinedEventMemoryEntry_1_GetDataIndex: start-on-event=GetDataIndex, operation=PS_NvMBlock_DemUserDefinedEventMemoryEntry_1.GetDataIndex
        OperationInvokedEvent_PS_NvMBlock_DemUserDefinedEventMemoryEntry_1_GetErrorStatus: start-on-event=GetErrorStatus, operation=PS_NvMBlock_DemUserDefinedEventMemoryEntry_1.GetErrorStatus
        OperationInvokedEvent_PS_NvMBlock_DemUserDefinedEventMemoryEntry_1_InvalidateNvBlock: start-on-event=InvalidateNvBlock, operation=PS_NvMBlock_DemUserDefinedEventMemoryEntry_1.InvalidateNvBlock
        OperationInvokedEvent_PS_NvMBlock_DemUserDefinedEventMemoryEntry_1_ReadBlock: start-on-event=ReadBlock, operation=PS_NvMBlock_DemUserDefinedEventMemoryEntry_1.ReadBlock
        OperationInvokedEvent_PS_NvMBlock_DemUserDefinedEventMemoryEntry_1_ReadPRAMBlock: start-on-event=ReadPRAMBlock, operation=PS_NvMBlock_DemUserDefinedEventMemoryEntry_1.ReadPRAMBlock
        OperationInvokedEvent_PS_NvMBlock_DemUserDefinedEventMemoryEntry_1_RestoreBlockDefaults: start-on-event=RestoreBlockDefaults, operation=PS_NvMBlock_DemUserDefinedEventMemoryEntry_1.RestoreBlockDefaults
        OperationInvokedEvent_PS_NvMBlock_DemUserDefinedEventMemoryEntry_1_RestorePRAMBlockDefaults: start-on-event=RestorePRAMBlockDefaults, operation=PS_NvMBlock_DemUserDefinedEventMemoryEntry_1.RestorePRAMBlockDefaults
        OperationInvokedEvent_PS_NvMBlock_DemUserDefinedEventMemoryEntry_1_SetDataIndex: start-on-event=SetDataIndex, operation=PS_NvMBlock_DemUserDefinedEventMemoryEntry_1.SetDataIndex
        OperationInvokedEvent_PS_NvMBlock_DemUserDefinedEventMemoryEntry_1_SetRamBlockStatus: start-on-event=SetRamBlockStatus, operation=PS_NvMBlock_DemUserDefinedEventMemoryEntry_1.SetRamBlockStatus
        OperationInvokedEvent_PS_NvMBlock_DemUserDefinedEventMemoryEntry_1_WriteBlock: start-on-event=WriteBlock, operation=PS_NvMBlock_DemUserDefinedEventMemoryEntry_1.WriteBlock
        OperationInvokedEvent_PS_NvMBlock_DemUserDefinedEventMemoryEntry_1_WritePRAMBlock: start-on-event=WritePRAMBlock, operation=PS_NvMBlock_DemUserDefinedEventMemoryEntry_1.WritePRAMBlock
        OperationInvokedEvent_PS_NvMBlock_DemUserDefinedEventMemoryEntry_2_EraseBlock: start-on-event=EraseBlock, operation=PS_NvMBlock_DemUserDefinedEventMemoryEntry_2.EraseBlock
        OperationInvokedEvent_PS_NvMBlock_DemUserDefinedEventMemoryEntry_2_GetDataIndex: start-on-event=GetDataIndex, operation=PS_NvMBlock_DemUserDefinedEventMemoryEntry_2.GetDataIndex
        OperationInvokedEvent_PS_NvMBlock_DemUserDefinedEventMemoryEntry_2_GetErrorStatus: start-on-event=GetErrorStatus, operation=PS_NvMBlock_DemUserDefinedEventMemoryEntry_2.GetErrorStatus
        OperationInvokedEvent_PS_NvMBlock_DemUserDefinedEventMemoryEntry_2_InvalidateNvBlock: start-on-event=InvalidateNvBlock, operation=PS_NvMBlock_DemUserDefinedEventMemoryEntry_2.InvalidateNvBlock
        OperationInvokedEvent_PS_NvMBlock_DemUserDefinedEventMemoryEntry_2_ReadBlock: start-on-event=ReadBlock, operation=PS_NvMBlock_DemUserDefinedEventMemoryEntry_2.ReadBlock
        OperationInvokedEvent_PS_NvMBlock_DemUserDefinedEventMemoryEntry_2_ReadPRAMBlock: start-on-event=ReadPRAMBlock, operation=PS_NvMBlock_DemUserDefinedEventMemoryEntry_2.ReadPRAMBlock
        OperationInvokedEvent_PS_NvMBlock_DemUserDefinedEventMemoryEntry_2_RestoreBlockDefaults: start-on-event=RestoreBlockDefaults, operation=PS_NvMBlock_DemUserDefinedEventMemoryEntry_2.RestoreBlockDefaults
        OperationInvokedEvent_PS_NvMBlock_DemUserDefinedEventMemoryEntry_2_RestorePRAMBlockDefaults: start-on-event=RestorePRAMBlockDefaults, operation=PS_NvMBlock_DemUserDefinedEventMemoryEntry_2.RestorePRAMBlockDefaults
        OperationInvokedEvent_PS_NvMBlock_DemUserDefinedEventMemoryEntry_2_SetDataIndex: start-on-event=SetDataIndex, operation=PS_NvMBlock_DemUserDefinedEventMemoryEntry_2.SetDataIndex
        OperationInvokedEvent_PS_NvMBlock_DemUserDefinedEventMemoryEntry_2_SetRamBlockStatus: start-on-event=SetRamBlockStatus, operation=PS_NvMBlock_DemUserDefinedEventMemoryEntry_2.SetRamBlockStatus
        OperationInvokedEvent_PS_NvMBlock_DemUserDefinedEventMemoryEntry_2_WriteBlock: start-on-event=WriteBlock, operation=PS_NvMBlock_DemUserDefinedEventMemoryEntry_2.WriteBlock
        OperationInvokedEvent_PS_NvMBlock_DemUserDefinedEventMemoryEntry_2_WritePRAMBlock: start-on-event=WritePRAMBlock, operation=PS_NvMBlock_DemUserDefinedEventMemoryEntry_2.WritePRAMBlock
        OperationInvokedEvent_PS_NvMBlock_Test_Native_6_EraseBlock: start-on-event=EraseBlock, operation=PS_NvMBlock_Test_Native_6.EraseBlock
        OperationInvokedEvent_PS_NvMBlock_Test_Native_6_GetDataIndex: start-on-event=GetDataIndex, operation=PS_NvMBlock_Test_Native_6.GetDataIndex
        OperationInvokedEvent_PS_NvMBlock_Test_Native_6_GetErrorStatus: start-on-event=GetErrorStatus, operation=PS_NvMBlock_Test_Native_6.GetErrorStatus
        OperationInvokedEvent_PS_NvMBlock_Test_Native_6_InvalidateNvBlock: start-on-event=InvalidateNvBlock, operation=PS_NvMBlock_Test_Native_6.InvalidateNvBlock
        OperationInvokedEvent_PS_NvMBlock_Test_Native_6_ReadBlock: start-on-event=ReadBlock, operation=PS_NvMBlock_Test_Native_6.ReadBlock
        OperationInvokedEvent_PS_NvMBlock_Test_Native_6_ReadPRAMBlock: start-on-event=ReadPRAMBlock, operation=PS_NvMBlock_Test_Native_6.ReadPRAMBlock
        OperationInvokedEvent_PS_NvMBlock_Test_Native_6_RestoreBlockDefaults: start-on-event=RestoreBlockDefaults, operation=PS_NvMBlock_Test_Native_6.RestoreBlockDefaults
        OperationInvokedEvent_PS_NvMBlock_Test_Native_6_RestorePRAMBlockDefaults: start-on-event=RestorePRAMBlockDefaults, operation=PS_NvMBlock_Test_Native_6.RestorePRAMBlockDefaults
        OperationInvokedEvent_PS_NvMBlock_Test_Native_6_SetDataIndex: start-on-event=SetDataIndex, operation=PS_NvMBlock_Test_Native_6.SetDataIndex
        OperationInvokedEvent_PS_NvMBlock_Test_Native_6_SetRamBlockStatus: start-on-event=SetRamBlockStatus, operation=PS_NvMBlock_Test_Native_6.SetRamBlockStatus
        OperationInvokedEvent_PS_NvMBlock_Test_Native_6_WriteBlock: start-on-event=WriteBlock, operation=PS_NvMBlock_Test_Native_6.WriteBlock
        OperationInvokedEvent_PS_NvMBlock_Test_Native_6_WritePRAMBlock: start-on-event=WritePRAMBlock, operation=PS_NvMBlock_Test_Native_6.WritePRAMBlock
      port-api-options:
        {enable-take-address=false, indirect-api=false, port-defined-argument-value{value=Block1:1, value-type=NvM_BlockIdType}, port=PS_NvMBlock_ConfigID}
        {enable-take-address=false, indirect-api=false, port-defined-argument-value{value=Block1:1, value-type=NvM_BlockIdType}, port=PAdmin_NvMBlock_ConfigID}
        {enable-take-address=false, indirect-api=false, port-defined-argument-value{value=Block2:2, value-type=NvM_BlockIdType}, port=PS_NvMBlock_DemNonVolatileData}
        {enable-take-address=false, indirect-api=false, port-defined-argument-value{value=Block2:2, value-type=NvM_BlockIdType}, port=PAdmin_NvMBlock_DemNonVolatileData}
        {enable-take-address=false, indirect-api=false, port-defined-argument-value{value=Block3:3, value-type=NvM_BlockIdType}, port=PS_NvMBlock_DemEventStatusNvRamBlock}
        {enable-take-address=false, indirect-api=false, port-defined-argument-value{value=Block3:3, value-type=NvM_BlockIdType}, port=PAdmin_NvMBlock_DemEventStatusNvRamBlock}
        {enable-take-address=false, indirect-api=false, port-defined-argument-value{value=Block4:4, value-type=NvM_BlockIdType}, port=PS_NvMBlock_DemPrimaryEventMemoryEntry_0}
        {enable-take-address=false, indirect-api=false, port-defined-argument-value{value=Block4:4, value-type=NvM_BlockIdType}, port=PAdmin_NvMBlock_DemPrimaryEventMemoryEntry_0}
        {enable-take-address=false, indirect-api=false, port-defined-argument-value{value=Block5:5, value-type=NvM_BlockIdType}, port=PS_NvMBlock_DemPrimaryEventMemoryEntry_1}
        {enable-take-address=false, indirect-api=false, port-defined-argument-value{value=Block5:5, value-type=NvM_BlockIdType}, port=PAdmin_NvMBlock_DemPrimaryEventMemoryEntry_1}
        {enable-take-address=false, indirect-api=false, port-defined-argument-value{value=Block6:6, value-type=NvM_BlockIdType}, port=PS_NvMBlock_DemPrimaryEventMemoryEntry_2}
        {enable-take-address=false, indirect-api=false, port-defined-argument-value{value=Block6:6, value-type=NvM_BlockIdType}, port=PAdmin_NvMBlock_DemPrimaryEventMemoryEntry_2}
        {enable-take-address=false, indirect-api=false, port-defined-argument-value{value=Block7:7, value-type=NvM_BlockIdType}, port=PS_NvMBlock_Test_Native_6}
        {enable-take-address=false, indirect-api=false, port-defined-argument-value{value=Block7:7, value-type=NvM_BlockIdType}, port=PAdmin_NvMBlock_Test_Native_6}
        {enable-take-address=false, indirect-api=false, port-defined-argument-value{value=Block8:8, value-type=NvM_BlockIdType}, port=PS_NvMBlock_DemUserDefinedEventMemoryEntry_0}
        {enable-take-address=false, indirect-api=false, port-defined-argument-value{value=Block8:8, value-type=NvM_BlockIdType}, port=PAdmin_NvMBlock_DemUserDefinedEventMemoryEntry_0}
        {enable-take-address=false, indirect-api=false, port-defined-argument-value{value=Block9:9, value-type=NvM_BlockIdType}, port=PS_NvMBlock_DemUserDefinedEventMemoryEntry_1}
        {enable-take-address=false, indirect-api=false, port-defined-argument-value{value=Block9:9, value-type=NvM_BlockIdType}, port=PAdmin_NvMBlock_DemUserDefinedEventMemoryEntry_1}
        {enable-take-address=false, indirect-api=false, port-defined-argument-value{value=Block10:10, value-type=NvM_BlockIdType}, port=PS_NvMBlock_DemUserDefinedEventMemoryEntry_2}
        {enable-take-address=false, indirect-api=false, port-defined-argument-value{value=Block10:10, value-type=NvM_BlockIdType}, port=PAdmin_NvMBlock_DemUserDefinedEventMemoryEntry_2}
        {enable-take-address=false, indirect-api=false, port-defined-argument-value{value=Block11:11, value-type=NvM_BlockIdType}, port=PS_NvMBlock_DemMirrorEventMemory_0}
        {enable-take-address=false, indirect-api=false, port-defined-argument-value{value=Block11:11, value-type=NvM_BlockIdType}, port=PAdmin_NvMBlock_DemMirrorEventMemory_0}
        {enable-take-address=false, indirect-api=false, port-defined-argument-value{value=Block12:12, value-type=NvM_BlockIdType}, port=PS_NvMBlock_DemMirrorEventMemory_1}
        {enable-take-address=false, indirect-api=false, port-defined-argument-value{value=Block12:12, value-type=NvM_BlockIdType}, port=PAdmin_NvMBlock_DemMirrorEventMemory_1}
        {enable-take-address=false, indirect-api=false, port-defined-argument-value{value=Block13:13, value-type=NvM_BlockIdType}, port=PS_NvMBlock_DemMirrorEventMemory_2}
        {enable-take-address=false, indirect-api=false, port-defined-argument-value{value=Block13:13, value-type=NvM_BlockIdType}, port=PAdmin_NvMBlock_DemMirrorEventMemory_2}
        {enable-take-address=false, indirect-api=false, port-defined-argument-value{value=Block14:14, value-type=NvM_BlockIdType}, port=PS_NvMBlock_DemPermanentEventMemory_0}
        {enable-take-address=false, indirect-api=false, port-defined-argument-value{value=Block14:14, value-type=NvM_BlockIdType}, port=PAdmin_NvMBlock_DemPermanentEventMemory_0}
        {enable-take-address=false, indirect-api=false, port-defined-argument-value{value=Block15:15, value-type=NvM_BlockIdType}, port=PS_NvMBlock_DemPermanentEventMemory_1}
        {enable-take-address=false, indirect-api=false, port-defined-argument-value{value=Block15:15, value-type=NvM_BlockIdType}, port=PAdmin_NvMBlock_DemPermanentEventMemory_1}
        {enable-take-address=false, indirect-api=false, port-defined-argument-value{value=Block16:16, value-type=NvM_BlockIdType}, port=PS_NvMBlock_DemPermanentEventMemory_2}
        {enable-take-address=false, indirect-api=false, port-defined-argument-value{value=Block16:16, value-type=NvM_BlockIdType}, port=PAdmin_NvMBlock_DemPermanentEventMemory_2}
      14 x runnable:
        EraseBlock: runnable-entity-argument=symbol=BlockId, can-be-invoked-concurrently=true, symbol=NvM_EraseNvBlock
        GetDataIndex: arguments=[symbol=BlockId, symbol=DataIndexPtr], can-be-invoked-concurrently=true, symbol=NvM_GetDataIndex
        GetErrorStatus: arguments=[symbol=BlockId, symbol=RequestResultPtr], can-be-invoked-concurrently=true, symbol=NvM_GetErrorStatus
        InvalidateNvBlock: runnable-entity-argument=symbol=BlockId, can-be-invoked-concurrently=true, symbol=NvM_InvalidateNvBlock
        MainFunction: symbol=NvM_MainFunction
        ReadBlock: arguments=[symbol=BlockId, symbol=DstPtr], can-be-invoked-concurrently=true, symbol=NvM_ReadBlock
        ReadPRAMBlock: runnable-entity-argument=symbol=BlockId, can-be-invoked-concurrently=true, symbol=NvM_ReadPRAMBlock
        RestoreBlockDefaults: arguments=[symbol=BlockId, symbol=DstPtr], can-be-invoked-concurrently=true, symbol=NvM_RestoreBlockDefaults
        RestorePRAMBlockDefaults: runnable-entity-argument=symbol=BlockId, can-be-invoked-concurrently=true, symbol=NvM_RestorePRAMBlockDefaults
        SetBlockProtection: arguments=[symbol=BlockId, symbol=ProtectionEnabled], can-be-invoked-concurrently=true, symbol=NvM_SetBlockProtection
        SetDataIndex: arguments=[symbol=BlockId, symbol=DataIndex], can-be-invoked-concurrently=true, symbol=NvM_SetDataIndex
        SetRamBlockStatus: arguments=[symbol=BlockId, symbol=BlockChanged], can-be-invoked-concurrently=true, symbol=NvM_SetRamBlockStatus
        WriteBlock: arguments=[symbol=BlockId, symbol=SrcPtr], can-be-invoked-concurrently=true, symbol=NvM_WriteBlock
        WritePRAMBlock: runnable-entity-argument=symbol=BlockId, can-be-invoked-concurrently=true, symbol=NvM_WritePRAMBlock
  swc bsw mapping SwcBswMapping_NvM: bsw-behavior=BswInternalBehavior_NvM, swc-bsw-runnable-mapping{bsw-entity=BswSE_NvM_MainFunction, swc-runnable=MainFunction}, swc-behavior=IB_NvM
  swc implementation SwcImplementation_NvM: programming-language=C, sw-version=1.3.2, swc-bsw-mapping=SwcBswMapping_NvM, vendor-id=76, behavior=IB_NvM
    code-descriptors:
      code Code: artifact-descriptors=autosar-engineering-object={short-label=NvM, category=SWOBJ}
    resource consumption ResourceConsumption
